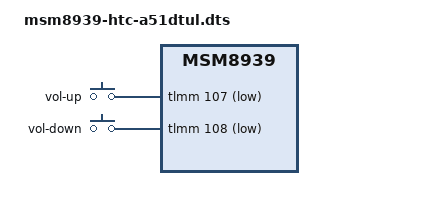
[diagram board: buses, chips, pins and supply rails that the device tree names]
// SPDX-License-Identifier: BSD-3-Clause

#include <skeleton64.dtsi>
#include <lk2nd.dtsi>

/*
 * 1. To build for htc-a51dtul, add LK2ND_QCDTBS="msm8939-htc-a51dtul.dtb" to
 * your make cmdline. With too many DTBs in ../rules.mk HBOOT refuses to boot:
 * [ERR] The device tree entry table should be LESS THAN a page (2048)
 * 2. In HBOOT `fastboot boot lk2nd.img` won't boot that image, instead it'll
 * boot whatever is currently flashed to boot partition.
 */

/ {
	// actually htc,project-id
	qcom,msm-id = <342 0x10000>, <343 0x10000>, <344 0x10000>, <345 0x10000>;
	// actually htc,hw-id
	qcom,board-id = <0x80 0>;
};

&lk2nd {
	model = "HTC Desire 820 Dual SIM";
	compatible = "htc,a51dtul";

	//FIXME: lk2nd,dtb-files = "msm8939-htc-a51dtul";

	gpio-keys {
		compatible = "gpio-keys";
		vol-up {
			lk2nd,code = <KEY_VOLUMEUP>;
			gpios = <&tlmm 107 (GPIO_ACTIVE_LOW | GPIO_PULL_UP)>;
		};
		vol-down {
			lk2nd,code = <KEY_VOLUMEDOWN>;
			gpios = <&tlmm 108 (GPIO_ACTIVE_LOW | GPIO_PULL_UP)>;
		};
	};
};
